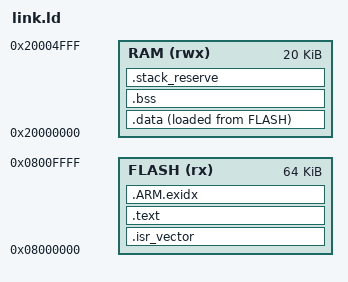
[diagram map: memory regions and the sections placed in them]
ENTRY(Reset_Handler)
MEMORY {
 FLASH (rx) : ORIGIN = 0x08000000, LENGTH = 64K
 RAM (rwx) : ORIGIN = 0x20000000, LENGTH = 20K
}
_estack = ORIGIN(RAM) + LENGTH(RAM);
SECTIONS {
 .isr_vector : { KEEP(*(.isr_vector)) } > FLASH
 .text : { *(.text*) *(.rodata*) . = ALIGN(4); } > FLASH
 .ARM.exidx : { *(.ARM.exidx*) } > FLASH
 .data : { . = ALIGN(4); _sdata = .; *(.data*) . = ALIGN(4); _edata = .; } > RAM AT> FLASH
 _sidata = LOADADDR(.data);
 .bss (NOLOAD) : { . = ALIGN(4); _sbss = .; *(.bss*) *(COMMON) . = ALIGN(4); _ebss = .; } > RAM
 .stack_reserve (NOLOAD) : { . = ALIGN(8); _stack_low = .; . += 1024; } > RAM
 /DISCARD/ : { *(.comment) *(.note*) }
}
ASSERT(_ebss + 1024 <= _estack, "RAM overflow: less than 1KB stack")

